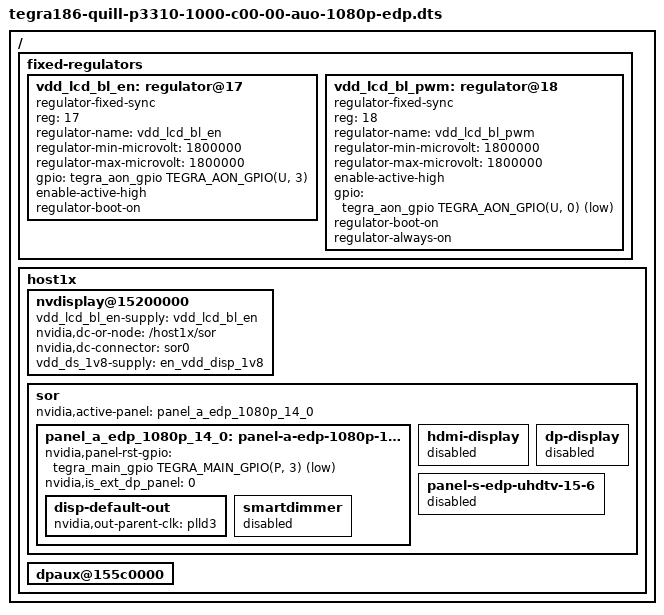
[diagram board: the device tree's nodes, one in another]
/*
 * Copyright (c) 2017, NVIDIA CORPORATION.  All rights reserved.
 *
 * This program is free software; you can redistribute it and/or modify
 * it under the terms of the GNU General Public License as published by
 * the Free Software Foundation; version 2 of the License.
 *
 * This program is distributed in the hope that it will be useful, but WITHOUT
 * ANY WARRANTY; without even the implied warranty of MERCHANTABILITY or
 * FITNESS FOR A PARTICULAR PURPOSE.  See the GNU General Public License for
 * more details.
 *
 * You should have received a copy of the GNU General Public License along
 * with this program; if not, write to the Free Software Foundation, Inc.,
 * 51 Franklin Street, Fifth Floor, Boston, MA  02110-1301, USA.
 *
 */

#include "tegra186-quill-p3310-1000-c03-00-base.dts"
/ {
	fixed-regulators {
		/* Quill eDP LCD backlight */
		vdd_lcd_bl_en: regulator@17 {
			compatible = "regulator-fixed-sync";
			reg = <17>;
			regulator-name = "vdd_lcd_bl_en";
			regulator-min-microvolt = <1800000>;
			regulator-max-microvolt = <1800000>;
			gpio = <&tegra_aon_gpio TEGRA_AON_GPIO(U, 3) 0>; /* GPIO_DIS3 for eDP */
			enable-active-high;
			regulator-boot-on;
		};
		/* HACK Quill eDP LCD backlight pwm */
		vdd_lcd_bl_pwm: regulator@18 {
			compatible = "regulator-fixed-sync";
			reg = <18>;
			regulator-name = "vdd_lcd_bl_pwm";
			regulator-min-microvolt = <1800000>;
			regulator-max-microvolt = <1800000>;
			enable-active-high;
			gpio = <&tegra_aon_gpio TEGRA_AON_GPIO(U, 0) 1>; /* GPIO_DIS0 for eDP */
			regulator-boot-on;
			regulator-always-on;
		};
	};

	host1x {

		nvdisplay@15200000 {
			status = "okay";
			vdd_lcd_bl_en-supply = <&vdd_lcd_bl_en>; /* GPIO_DIS3 / LCD_BL_EN for eDP */
			nvidia,dc-or-node = "/host1x/sor";
			nvidia,dc-connector = <&sor0>;
			vdd_ds_1v8-supply = <&en_vdd_disp_1v8>;
                };

		sor {
			status = "okay";
			nvidia,active-panel = <&panel_a_edp_1080p_14_0>;
			/*
			 * Note: Since this dts doesn't include panel dtsi,
			 *       panels/panel-a-edp-1080p-14-0.dtsi, dtc
			 *       doesn't find label "panel_a_edp_1080p_14_0".
			 *       For now define the label here but correct
			 *       fix should be to include
			 *       panels/panel-a-edp-1080p-14-0.dtsi and then
			 *       update the settings.
			 */
			panel_a_edp_1080p_14_0: panel-a-edp-1080p-14-0 {
				status = "okay";
				nvidia,panel-rst-gpio = <&tegra_main_gpio TEGRA_MAIN_GPIO(P, 3) 1>; /* PP3 */
				nvidia,is_ext_dp_panel = <0>;

				disp-default-out {
					/* SOR0->eDP on plld3; SOR1->HDMI on plld2 */
					nvidia,out-parent-clk = "plld3";
				};
				smartdimmer {
					status = "disabled";
				};
			};
			hdmi-display {
				status = "disabled";
			};
			dp-display {
				status = "disabled";
			};
			panel-s-edp-uhdtv-15-6 {
				status = "disabled";
			};
		};

		dpaux@155c0000 {
			status = "okay";
		};
	};
};
